# STM32F7x7 register map
File version: 1.6
CPU: CM7 r0p0, little endian, no MPU, no FPU, 3 interrupt priority bits
Registers are 32-bit, read-write, reset 0x0 unless marked. A register's access mark holds for its fields unless they carry their own. Offsets are from the block's base; [hi:lo] are bit positions.

## PWR — Power control
Base 0x40007000
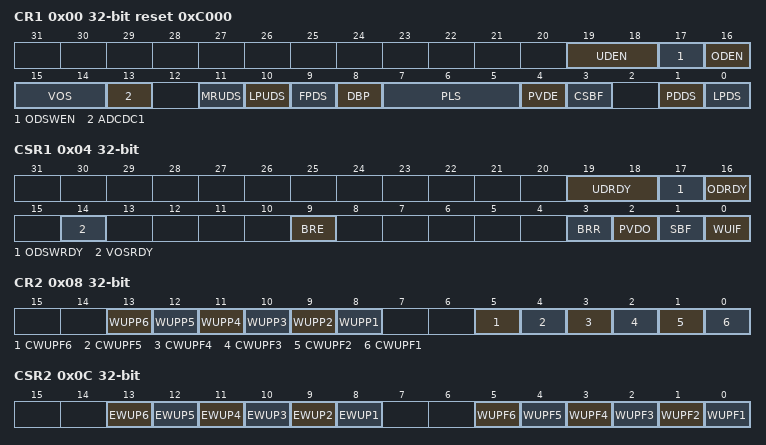
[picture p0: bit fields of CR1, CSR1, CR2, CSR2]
0x00 CR1 reset 0xC000 — power control register
  [19:18] UDEN — Under-drive enable in stop mode
  [17] ODSWEN — Over-drive switching enabled
  [16] ODEN — Over-drive enable
  [15:14] VOS — Regulator voltage scaling output selection
  [13] ADCDC1
  [11] MRUDS — Main regulator in deepsleep under-drive mode
  [10] LPUDS — Low-power regulator in deepsleep under-drive mode
  [9] FPDS — Flash power down in Stop mode
  [8] DBP — Disable backup domain write protection
  [7:5] PLS — PVD level selection
  [4] PVDE — Power voltage detector enable
  [3] CSBF — Clear standby flag
  [1] PDDS — Power down deepsleep
  [0] LPDS — Low-power deep sleep
0x04 CSR1 access per field — power control/status register
  [19:18] UDRDY rw — Under-drive ready flag
  [17] ODSWRDY rw — Over-drive mode switching ready
  [16] ODRDY rw — Over-drive mode ready
  [14] VOSRDY rw — Regulator voltage scaling output selection ready bit
  [9] BRE rw — Backup regulator enable
  [3] BRR ro — Backup regulator ready
  [2] PVDO ro — PVD output
  [1] SBF ro — Standby flag
  [0] WUIF ro — Wakeup internal flag
0x08 CR2 access per field — power control register
  [13] WUPP6 rw — Wakeup pin polarity bit for PI11
  [12] WUPP5 rw — Wakeup pin polarity bit for PI8
  [11] WUPP4 rw — Wakeup pin polarity bit for PC13
  [10] WUPP3 rw — Wakeup pin polarity bit for PC1
  [9] WUPP2 rw — Wakeup pin polarity bit for PA2
  [8] WUPP1 rw — Wakeup pin polarity bit for PA0
  [5] CWUPF6 ro — Clear Wakeup Pin flag for PI11
  [4] CWUPF5 ro — Clear Wakeup Pin flag for PI8
  [3] CWUPF4 ro — Clear Wakeup Pin flag for PC13
  [2] CWUPF3 ro — Clear Wakeup Pin flag for PC1
  [1] CWUPF2 ro — Clear Wakeup Pin flag for PA2
  [0] CWUPF1 ro — Clear Wakeup Pin flag for PA0
0x0C CSR2 access per field — power control/status register
  [13] EWUP6 rw — Enable Wakeup pin for PI11
  [12] EWUP5 rw — Enable Wakeup pin for PI8
  [11] EWUP4 rw — Enable Wakeup pin for PC13
  [10] EWUP3 rw — Enable Wakeup pin for PC1
  [9] EWUP2 rw — Enable Wakeup pin for PA2
  [8] EWUP1 rw — Enable Wakeup pin for PA0
  [5] WUPF6 ro — Wakeup Pin flag for PI11
  [4] WUPF5 ro — Wakeup Pin flag for PI8
  [3] WUPF4 ro — Wakeup Pin flag for PC13
  [2] WUPF3 ro — Wakeup Pin flag for PC1
  [1] WUPF2 ro — Wakeup Pin flag for PA2
  [0] WUPF1 ro — Wakeup Pin flag for PA0

## IWDG — Independent watchdog
Base 0x40003000
0x00 KR wo — Key register
  [15:0] KEY — Key value (write only, read 0000h)
0x04 PR — Prescaler register
  [2:0] PR — Prescaler divider
0x08 RLR reset 0xFFF — Reload register
  [11:0] RL — Watchdog counter reload value
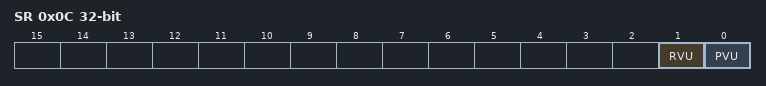
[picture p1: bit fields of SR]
0x0C SR ro — Status register
  [1] RVU — Watchdog counter reload value update
  [0] PVU — Watchdog prescaler value update
0x10 WINR — Window register
  [11:0] WIN — Watchdog counter window value

## WWDG — Window watchdog
Base 0x40002C00
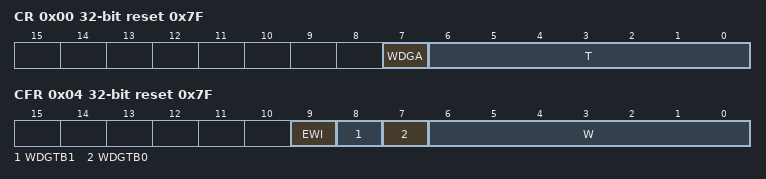
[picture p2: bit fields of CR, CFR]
0x00 CR reset 0x7F — Control register
  [7] WDGA — Activation bit
  [6:0] T — 7-bit counter (MSB to LSB)
0x04 CFR reset 0x7F — Configuration register
  [9] EWI — Early wakeup interrupt
  [8] WDGTB1 — Timer base
  [7] WDGTB0 — Timer base
  [6:0] W — 7-bit window value
0x08 SR — Status register
  [0] EWIF — Early wakeup interrupt flag

## TIM9 — General purpose timers
Base 0x40014000
Same registers: TIM12 0x40001800
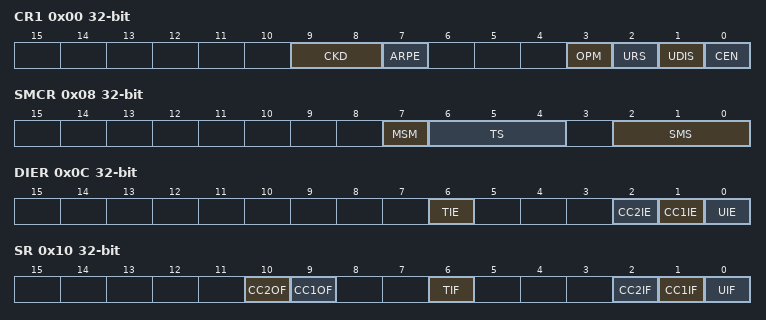
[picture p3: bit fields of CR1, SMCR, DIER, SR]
0x00 CR1 — control register 1
  [9:8] CKD — Clock division
  [7] ARPE — Auto-reload preload enable
  [3] OPM — One-pulse mode
  [2] URS — Update request source
  [1] UDIS — Update disable
  [0] CEN — Counter enable
0x08 SMCR — slave mode control register
  [7] MSM — Master/Slave mode
  [6:4] TS — Trigger selection
  [2:0] SMS — Slave mode selection
0x0C DIER — DMA/Interrupt enable register
  [6] TIE — Trigger interrupt enable
  [2] CC2IE — Capture/Compare 2 interrupt enable
  [1] CC1IE — Capture/Compare 1 interrupt enable
  [0] UIE — Update interrupt enable
0x10 SR — status register
  [10] CC2OF — Capture/compare 2 overcapture flag
  [9] CC1OF — Capture/Compare 1 overcapture flag
  [6] TIF — Trigger interrupt flag
  [2] CC2IF — Capture/Compare 2 interrupt flag
  [1] CC1IF — Capture/compare 1 interrupt flag
  [0] UIF — Update interrupt flag
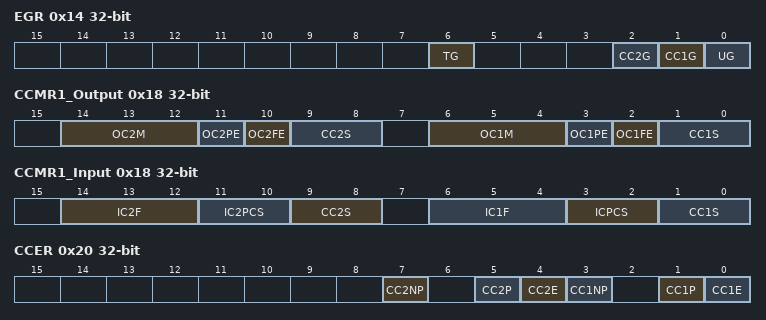
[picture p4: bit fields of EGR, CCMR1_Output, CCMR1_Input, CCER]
0x14 EGR wo — event generation register
  [6] TG — Trigger generation
  [2] CC2G — Capture/compare 2 generation
  [1] CC1G — Capture/compare 1 generation
  [0] UG — Update generation
0x18 CCMR1_Output — capture/compare mode register 1 (output mode)
  [14:12] OC2M — Output Compare 2 mode
  [11] OC2PE — Output Compare 2 preload enable
  [10] OC2FE — Output Compare 2 fast enable
  [9:8] CC2S — Capture/Compare 2 selection
  [6:4] OC1M — Output Compare 1 mode
  [3] OC1PE — Output Compare 1 preload enable
  [2] OC1FE — Output Compare 1 fast enable
  [1:0] CC1S — Capture/Compare 1 selection
0x18 CCMR1_Input (alternate view of CCMR1_Output) — capture/compare mode register 1 (input mode)
  [14:12] IC2F — Input capture 2 filter
  [11:10] IC2PCS — Input capture 2 prescaler
  [9:8] CC2S — Capture/Compare 2 selection
  [6:4] IC1F — Input capture 1 filter
  [3:2] ICPCS — Input capture 1 prescaler
  [1:0] CC1S — Capture/Compare 1 selection
0x20 CCER — capture/compare enable register
  [7] CC2NP — Capture/Compare 2 output Polarity
  [5] CC2P — Capture/Compare 2 output Polarity
  [4] CC2E — Capture/Compare 2 output enable
  [3] CC1NP — Capture/Compare 1 output Polarity
  [1] CC1P — Capture/Compare 1 output Polarity
  [0] CC1E — Capture/Compare 1 output enable
0x24 CNT — counter
  [15:0] CNT — counter value
0x28 PSC — prescaler
  [15:0] PSC — Prescaler value
0x2C ARR — auto-reload register
  [15:0] ARR — Auto-reload value
0x34 CCR1 — capture/compare register 1
  [15:0] CCR1 — Capture/Compare 1 value
0x38 CCR2 — capture/compare register 2
  [15:0] CCR2 — Capture/Compare 2 value
